# A31G12x register map
Vendor: VENDOR ABOV Semiconductor Co., Ltd.; Series: A31G12x; File version: 1.0
CPU: CM0+ r0p1, little endian, no MPU, no FPU, VTOR, 2 interrupt priority bits
Registers are 32-bit, read-write, reset 0x0 unless marked. A register's access mark holds for its fields unless they carry their own. Offsets are from the block's base; [hi:lo] are bit positions; 'fields as' and 'values as' point back to an identical list.

## WT — Watch Timer
Base 0x40002000
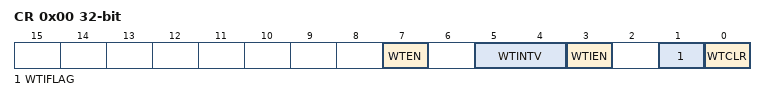
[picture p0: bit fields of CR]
0x00 CR — Watch Timer Control Register
  [7] WTEN — Watch Timer Operation Enable
    0=Disable watch timer operation; 1=Enable watch timer operation
  [5:4] WTINTV — Watch Timer Interval Selection
    0=fWT2Pow7 (fWT/2^7); 1=fWT2Pow13 (fWT/2^13); 2=fWT2Pow14 (fWT/2^14); 3=fWT2Pow14DR (fWT/(2^14x(WTDR value + 1)))
  [3] WTIEN — Watch Timer Interrupt Enable
    0=Disable watch timer interrupt; 1=Enable watch timer interrupt
  [1] WTIFLAG — Watch Timer Interrupt Flag
    0=No request occurred; 1=Request occurred
  [0] WTCLR — Watch Timer Counter and Divider Clear
    0=NoEffect; 1=Clear the counter and divider. (Automatically cleared to '0b' after operation)
0x04 DR reset 0xFFF — Watch Timer Data Register
  [11:0] WTDATA — Watch Timer Data
0x08 CNT ro — Watch Timer Counter Register
  [11:0] CNT — Watch Timer Counter

## TIMER1n — Timer/Counter 1n
Base 0x51000000
Same registers: TIMER10 0x40002100, TIMER11 0x40002200, TIMER12 0x40002300, TIMER13 0x40002700, TIMER14 0x40002800, TIMER15 0x40002900, TIMER16 0x40002A00
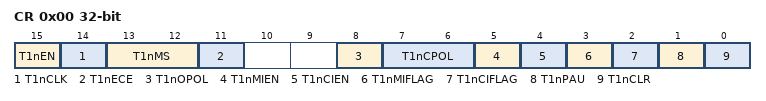
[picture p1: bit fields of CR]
0x00 CR — TIMER1n Control Register
  [15] T1nEN — TIMER1n Operation Enable
  [14] T1nCLK — TIMER1n Clock Selection
  [13:12] T1nMS — TIMER1n Operation Mode Selection
  [11] T1nECE — TIMER1n External Clock Edge Selection
  [8] T1nOPOL — TIMER1n Output Polarity Selection
  [7:6] T1nCPOL — TIMER1n Capture Polarity Selection
  [5] T1nMIEN — TIMER1n Match Interrupt Enable
  [4] T1nCIEN — TIMER1n Capture Interrupt Enable
  [3] T1nMIFLAG — TIMER1n Match Interrupt Flag
  [2] T1nCIFLAG — TIMER1n Capture Interrupt Flag
  [1] T1nPAU — TIMER1n Counter Temporary Pause Control
  [0] T1nCLR — TIMER1n Counter and Prescaler Clear
0x04 ADR reset 0xFFFF — TIMER1n A Data Register
  [15:0] ADATA — TIMER1n A Data
0x08 BDR reset 0xFFFF — TIMER1n B Data Register
  [15:0] BDATA — TIMER1n B Data
0x0C CAPDR ro — TIMER1n Capture Data Register
  [15:0] CAPD — TIMER1n Capture Data
0x10 PREDR reset 0xFFF — TIMER1n Prescaler Data Register
  [11:0] PRED — TIMER1n Prescaler Data
0x14 CNT ro — TIMER1n Counter Register
  [15:0] CNT — TIMER1n Counter

## TIMER2n — Timer/Counter 2n
Base 0x52000000
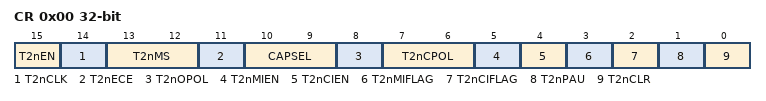
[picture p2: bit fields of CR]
0x00 CR — TIMER2n Control Register
  [15] T2nEN — TIMER2n Operation Enable
  [14] T2nCLK — TIMER2n Clock Selection
  [13:12] T2nMS — TIMER2n Operation Mode Selection
  [11] T2nECE — TIMER2n External Clock Edge Selection
  [10:9] CAPSEL — TIMER2n Capture Signal Selection
  [8] T2nOPOL — TIMER2n Output Polarity Selection
  [7:6] T2nCPOL — TIMER2n Capture Polarity Selection
  [5] T2nMIEN — TIMER2n Match Interrupt Enable
  [4] T2nCIEN — TIMER2n Capture Interrupt Enable
  [3] T2nMIFLAG — TIMER2n Match Interrupt Flag
  [2] T2nCIFLAG — TIMER2n Capture Interrupt Flag
  [1] T2nPAU — TIMER2n Counter Temporary Pause Control
  [0] T2nCLR — TIMER2n Counter and Prescaler Clear
0x04 ADR reset 0xFFFFFFFF — TIMER2n A Data Register
  [31:0] ADATA — TIMER2n A Data
0x08 BDR reset 0xFFFFFFFF — TIMER2n B Data Register
  [31:0] BDATA — TIMER2n B Data
0x0C CAPDR ro — TIMER2n Capture Data Register
  [31:0] CAPD — TIMER2n Capture Data
0x10 PREDR reset 0xFFF — TIMER2n Prescaler Data Register
  [11:0] PRED — TIMER2n Prescaler Data
0x14 CNT ro — TIMER2n Counter Register
  [31:0] CNT — TIMER2n Counter

## TIMER20 — Timer/Counter 20
Base 0x40002500
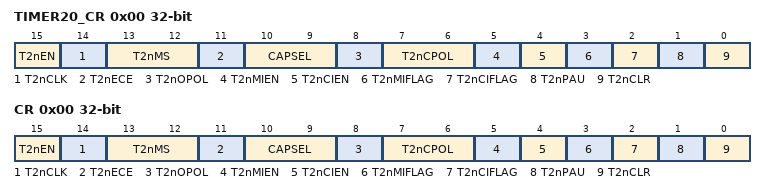
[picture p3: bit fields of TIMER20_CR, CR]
0x00 TIMER20_CR (alternate view of CR) — TIMER2n Control Register
  [15] T2nEN — TIMER2n Operation Enable
  [14] T2nCLK — TIMER2n Clock Selection
  [13:12] T2nMS — TIMER2n Operation Mode Selection
  [11] T2nECE — TIMER2n External Clock Edge Selection
  [10:9] CAPSEL — TIMER2n Capture Signal Selection
  [8] T2nOPOL — TIMER2n Output Polarity Selection
  [7:6] T2nCPOL — TIMER2n Capture Polarity Selection
  [5] T2nMIEN — TIMER2n Match Interrupt Enable
  [4] T2nCIEN — TIMER2n Capture Interrupt Enable
  [3] T2nMIFLAG — TIMER2n Match Interrupt Flag
  [2] T2nCIFLAG — TIMER2n Capture Interrupt Flag
  [1] T2nPAU — TIMER2n Counter Temporary Pause Control
  [0] T2nCLR — TIMER2n Counter and Prescaler Clear
0x00 CR — TIMER2n Control Register
  fields as TIMER20_CR
0x04 ADR reset 0xFFFFFFFF — TIMER2n A Data Register
  [31:0] ADATA — TIMER2n A Data
0x08 BDR reset 0xFFFFFFFF — TIMER2n B Data Register
  [31:0] BDATA — TIMER2n B Data
0x0C CAPDR ro — TIMER2n Capture Data Register
  [31:0] CAPD — TIMER2n Capture Data
0x10 PREDR reset 0xFFF — TIMER2n Prescaler Data Register
  [11:0] PRED — TIMER2n Prescaler Data
0x14 CNT ro — TIMER2n Counter Register
  [31:0] CNT — TIMER2n Counter

## TIMER21 — Timer/Counter 21
Base 0x40002600
Registers as TIMER20 (with TIMER20 read as TIMER21); these are added or differ:
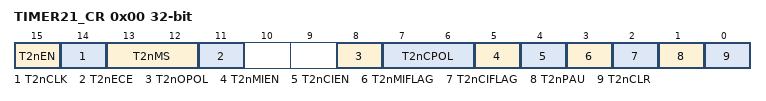
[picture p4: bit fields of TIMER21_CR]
0x00 TIMER21_CR (alternate view of CR) — TIMER2n Control Register
  [15] T2nEN — TIMER2n Operation Enable
  [14] T2nCLK — TIMER2n Clock Selection
  [13:12] T2nMS — TIMER2n Operation Mode Selection
  [11] T2nECE — TIMER2n External Clock Edge Selection
  [8] T2nOPOL — TIMER2n Output Polarity Selection
  [7:6] T2nCPOL — TIMER2n Capture Polarity Selection
  [5] T2nMIEN — TIMER2n Match Interrupt Enable
  [4] T2nCIEN — TIMER2n Capture Interrupt Enable
  [3] T2nMIFLAG — TIMER2n Match Interrupt Flag
  [2] T2nCIFLAG — TIMER2n Capture Interrupt Flag
  [1] T2nPAU — TIMER2n Counter Temporary Pause Control
  [0] T2nCLR — TIMER2n Counter and Prescaler Clear
